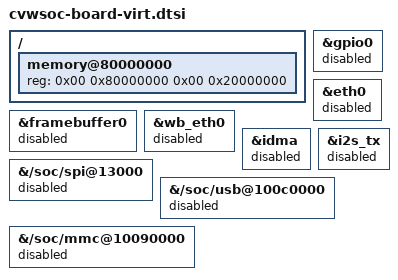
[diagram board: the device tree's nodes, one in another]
/ {
  memory@80000000 {
    device_type = "memory";
    reg = <0x00 0x80000000 0x00 0x20000000>;
  };
};

// Peripherals absent from the default virtual setup.
&framebuffer0 { status = "disabled"; };
&gpio0 { status = "disabled"; };
&eth0 { status = "disabled"; };
&wb_eth0 { status = "disabled"; };
&idma { status = "disabled"; };
&i2s_tx { status = "disabled"; };
&{/soc/spi@13000} { status = "disabled"; };
&{/soc/usb@100c0000} { status = "disabled"; };
&{/soc/mmc@10090000} { status = "disabled"; };
